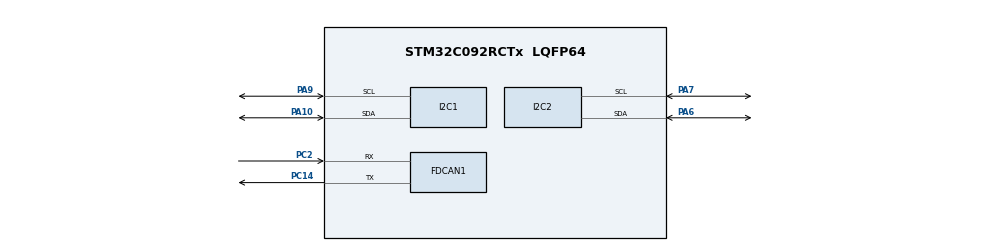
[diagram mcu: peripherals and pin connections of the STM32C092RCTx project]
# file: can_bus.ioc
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FDCAN1.AutoRetransmission=ENABLE
FDCAN1.CalculateBaudRateNominal=1000000
FDCAN1.CalculateTimeBitNominal=1000
FDCAN1.CalculateTimeQuantumNominal=20.833333333333332
FDCAN1.DataSyncJumpWidth=6
FDCAN1.DataTimeSeg1=17
FDCAN1.DataTimeSeg2=6
FDCAN1.NominalPrescaler=1
FDCAN1.NominalSyncJumpWidth=12
FDCAN1.NominalTimeSeg1=35
FDCAN1.NominalTimeSeg2=12
FDCAN1.StdFiltersNbr=1
FDCAN1.TransmitPause=ENABLE
I2C1.Timing=0x10805D88
I2C2.Timing=0x10805D88
Mcu.Family=STM32C0
Mcu.Name=STM32C092RCTx
Mcu.Package=LQFP64
PA10.Mode=I2C
PA10.Signal=I2C1_SDA
PA6.Mode=I2C
PA6.Signal=I2C2_SDA
PA7.Mode=I2C
PA7.Signal=I2C2_SCL
PA9.Mode=I2C
PA9.Signal=I2C1_SCL
PC14-OSCX_IN(PC14).Mode=FDCAN_Activate
PC14-OSCX_IN(PC14).Signal=FDCAN1_TX
PC2.Mode=FDCAN_Activate
PC2.Signal=FDCAN1_RX
ProjectManager.HeapSize=0x200
ProjectManager.StackSize=0x400
ProjectManager.TargetToolchain=STM32CubeIDE
RCC.ADCFreq_Value=48000000
RCC.AHBFreq_Value=48000000
RCC.CortexFreq_Value=48000000
RCC.EXTERNAL_CLOCK_VALUE=12288000
RCC.HCLKFreq_Value=48000000
RCC.HSE_VALUE=8000000
RCC.HSISYSCLKDivider=RCC_HSI_DIV1
RCC.HSI_VALUE=48000000
RCC.LSE_VALUE=32768
RCC.SYSCLKFreq_VALUE=48000000
board=custom

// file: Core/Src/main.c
/* USER CODE BEGIN Header */
/**
  ******************************************************************************
  * @file           : main.c
  * @brief          : Main program body
  ******************************************************************************
  * @attention
  *
  * Copyright (c) 2026 STMicroelectronics.
  * All rights reserved.
  *
  * This software is licensed under terms that can be found in the LICENSE file
  * in the root directory of this software component.
  * If no LICENSE file comes with this software, it is provided AS-IS.
  *
  ******************************************************************************
  */
/* USER CODE END Header */
#include "main.h"

/* USER CODE BEGIN PD */
#define TX_ID          (0x444)   /* TX CAN message identifier    */
#define RX_ID          (0x444)   /* RX CAN message identifier    */
/* USER CODE END PD */

FDCAN_HandleTypeDef hfdcan1;

I2C_HandleTypeDef hi2c1;
I2C_HandleTypeDef hi2c2;
/* USER CODE END PM */

FDCAN_HandleTypeDef hfdcan1;

/* USER CODE BEGIN PV */
FDCAN_RxHeaderTypeDef rxHeader;
FDCAN_TxHeaderTypeDef txHeader;
uint8_t rxData[2U];
static const uint8_t txData[] = {0xAB, 0xCD};

void SystemClock_Config(void);
static void MX_GPIO_Init(void);
static void MX_FDCAN1_Init(void);
static void MX_I2C1_Init(void);
static void MX_I2C2_Init(void);

int main(void)
{
	/* Reset of all peripherals, Initializes the Flash interface and the Systick. */
	HAL_Init();

	/* Configure the system clock */
	SystemClock_Config();

	/* Initialize all configured peripherals */
	MX_GPIO_Init();
	MX_FDCAN1_Init();
	MX_I2C1_Init();
	MX_I2C2_Init();
	/* Configure reception filter to Rx FIFO 0 */
	FDCAN_FilterTypeDef        sFilterConfig;
	sFilterConfig.IdType       = FDCAN_STANDARD_ID;
	sFilterConfig.FilterIndex  = 0U;
	sFilterConfig.FilterType   = FDCAN_FILTER_MASK;
	sFilterConfig.FilterConfig = FDCAN_FILTER_TO_RXFIFO0;
	sFilterConfig.FilterID1    = TX_ID;
	sFilterConfig.FilterID2    = 0x7FF;
	if (HAL_FDCAN_ConfigFilter(&hfdcan1, &sFilterConfig) != HAL_OK)
	{
		Error_Handler();
	}

	/**Configure global filter:
	    *    - Filter all remote frames with STD and EXT ID
	    *    - Reject non matching frames with STD ID and EXT ID
	    */
	if (HAL_FDCAN_ConfigGlobalFilter(&hfdcan1, FDCAN_REJECT, FDCAN_REJECT, FDCAN_FILTER_REMOTE, FDCAN_FILTER_REMOTE) != HAL_OK)
	{
		Error_Handler();
	}

	/* Activate Rx FIFO 0 new message notification */
	if (HAL_FDCAN_ActivateNotification(&hfdcan1, FDCAN_IT_RX_FIFO0_NEW_MESSAGE, 0U) != HAL_OK)
	{
		Error_Handler();
	}

	/* Prepare Tx message Header */
	txHeader.Identifier          = TX_ID;
	txHeader.IdType              = FDCAN_STANDARD_ID;
	txHeader.TxFrameType         = FDCAN_DATA_FRAME;
	txHeader.DataLength          = FDCAN_DLC_BYTES_2;
	txHeader.ErrorStateIndicator = FDCAN_ESI_ACTIVE;
	txHeader.BitRateSwitch       = FDCAN_BRS_OFF;
	txHeader.FDFormat            = FDCAN_CLASSIC_CAN;
	txHeader.TxEventFifoControl  = FDCAN_NO_TX_EVENTS;
	txHeader.MessageMarker       = 0U;

	/* Start FDCAN controller */
	if (HAL_FDCAN_Start(&hfdcan1) != HAL_OK){
		Error_Handler();
	}

	/* USER CODE BEGIN WHILE */
	while (1)
	{
		/* Add message to TX FIFO */
		if (HAL_FDCAN_AddMessageToTxFifoQ(&hfdcan1, &txHeader, txData) != HAL_OK){
			Error_Handler();
		}
		HAL_Delay(1000);
	}
}

void SystemClock_Config(void)
{
  RCC_OscInitTypeDef RCC_OscInitStruct = {0};
  RCC_ClkInitTypeDef RCC_ClkInitStruct = {0};

  __HAL_FLASH_SET_LATENCY(FLASH_LATENCY_1);

  /** Initializes the RCC Oscillators according to the specified parameters
  * in the RCC_OscInitTypeDef structure.
  */
  RCC_OscInitStruct.OscillatorType = RCC_OSCILLATORTYPE_HSI;
  RCC_OscInitStruct.HSIState = RCC_HSI_ON;
  RCC_OscInitStruct.HSIDiv = RCC_HSI_DIV1;
  RCC_OscInitStruct.HSICalibrationValue = RCC_HSICALIBRATION_DEFAULT;
  if (HAL_RCC_OscConfig(&RCC_OscInitStruct) != HAL_OK)
  {
    Error_Handler();
  }

  /** Initializes the CPU, AHB and APB buses clocks
  */
  RCC_ClkInitStruct.ClockType = RCC_CLOCKTYPE_HCLK|RCC_CLOCKTYPE_SYSCLK
                              |RCC_CLOCKTYPE_PCLK1;
  RCC_ClkInitStruct.SYSCLKSource = RCC_SYSCLKSOURCE_HSI;
  RCC_ClkInitStruct.SYSCLKDivider = RCC_SYSCLK_DIV1;
  RCC_ClkInitStruct.AHBCLKDivider = RCC_HCLK_DIV1;
  RCC_ClkInitStruct.APB1CLKDivider = RCC_APB1_DIV1;

  if (HAL_RCC_ClockConfig(&RCC_ClkInitStruct, FLASH_LATENCY_1) != HAL_OK)
  {
    Error_Handler();
  }
}

static void MX_FDCAN1_Init(void)
{

  hfdcan1.Instance = FDCAN1;
  hfdcan1.Init.ClockDivider = FDCAN_CLOCK_DIV1;
  hfdcan1.Init.FrameFormat = FDCAN_FRAME_CLASSIC;
  hfdcan1.Init.Mode = FDCAN_MODE_NORMAL;
  hfdcan1.Init.AutoRetransmission = ENABLE;
  hfdcan1.Init.TransmitPause = ENABLE;
  hfdcan1.Init.ProtocolException = DISABLE;
  hfdcan1.Init.NominalPrescaler = 1;
  hfdcan1.Init.NominalSyncJumpWidth = 12;
  hfdcan1.Init.NominalTimeSeg1 = 35;
  hfdcan1.Init.NominalTimeSeg2 = 12;
  hfdcan1.Init.DataPrescaler = 1;
  hfdcan1.Init.DataSyncJumpWidth = 6;
  hfdcan1.Init.DataTimeSeg1 = 17;
  hfdcan1.Init.DataTimeSeg2 = 6;
  hfdcan1.Init.StdFiltersNbr = 1;
  hfdcan1.Init.ExtFiltersNbr = 0;
  hfdcan1.Init.TxFifoQueueMode = FDCAN_TX_FIFO_OPERATION;
  if (HAL_FDCAN_Init(&hfdcan1) != HAL_OK)
  {
    Error_Handler();
  }

}

static void MX_I2C1_Init(void)
{

  hi2c1.Instance = I2C1;
  hi2c1.Init.Timing = 0x10805D88;
  hi2c1.Init.OwnAddress1 = 0;
  hi2c1.Init.AddressingMode = I2C_ADDRESSINGMODE_7BIT;
  hi2c1.Init.DualAddressMode = I2C_DUALADDRESS_DISABLE;
  hi2c1.Init.OwnAddress2 = 0;
  hi2c1.Init.OwnAddress2Masks = I2C_OA2_NOMASK;
  hi2c1.Init.GeneralCallMode = I2C_GENERALCALL_DISABLE;
  hi2c1.Init.NoStretchMode = I2C_NOSTRETCH_DISABLE;
  if (HAL_I2C_Init(&hi2c1) != HAL_OK)
  {
    Error_Handler();
  }

  /** Configure Analogue filter
  */
  if (HAL_I2CEx_ConfigAnalogFilter(&hi2c1, I2C_ANALOGFILTER_ENABLE) != HAL_OK)
  {
    Error_Handler();
  }

  /** Configure Digital filter
  */
  if (HAL_I2CEx_ConfigDigitalFilter(&hi2c1, 0) != HAL_OK)
  {
    Error_Handler();
  }

}

static void MX_I2C2_Init(void)
{

  hi2c2.Instance = I2C2;
  hi2c2.Init.Timing = 0x10805D88;
  hi2c2.Init.OwnAddress1 = 0;
  hi2c2.Init.AddressingMode = I2C_ADDRESSINGMODE_7BIT;
  hi2c2.Init.DualAddressMode = I2C_DUALADDRESS_DISABLE;
  hi2c2.Init.OwnAddress2 = 0;
  hi2c2.Init.OwnAddress2Masks = I2C_OA2_NOMASK;
  hi2c2.Init.GeneralCallMode = I2C_GENERALCALL_DISABLE;
  hi2c2.Init.NoStretchMode = I2C_NOSTRETCH_DISABLE;
  if (HAL_I2C_Init(&hi2c2) != HAL_OK)
  {
    Error_Handler();
  }

  /** Configure Analogue filter
  */
  if (HAL_I2CEx_ConfigAnalogFilter(&hi2c2, I2C_ANALOGFILTER_ENABLE) != HAL_OK)
  {
    Error_Handler();
  }

  /** Configure Digital filter
  */
  if (HAL_I2CEx_ConfigDigitalFilter(&hi2c2, 0) != HAL_OK)
  {
    Error_Handler();
  }

}

static void MX_GPIO_Init(void)
{

  /* GPIO Ports Clock Enable */
  __HAL_RCC_GPIOC_CLK_ENABLE();
  __HAL_RCC_GPIOA_CLK_ENABLE();

}

void Error_Handler(void)
{
  __disable_irq();
  while (1)
  {
  }
}
